AUTOSAR XML (schema 00046)
package /SWComponents
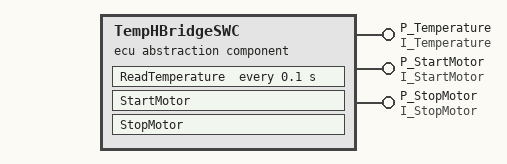
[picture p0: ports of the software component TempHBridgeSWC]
  ecu abstraction sw component type TempHBridgeSWC
    provide port P_Temperature: provided-interface=I_Temperature
    provide port P_StartMotor: provided-interface=I_StartMotor
    provide port P_StopMotor: provided-interface=I_StopMotor
    behavior IB_SWC
      timing event TE_10ms: start-on-event=ReadTemperature, period=0.1
      operation invoked event OIE_StartMotor: start-on-event=StartMotor, operation=P_StartMotor.StartMotor
      operation invoked event OIE_StopMotor: start-on-event=StopMotor, operation=P_StopMotor.StopMotor
      runnable ReadTemperature: symbol=ReadTemperature_Function
        data-send-points:
          access VA_Temp: accessed-variable=P_Temperature.Temperature
      runnable StartMotor: symbol=StartMotor_Function
      runnable StopMotor: symbol=StopMotor_Function
